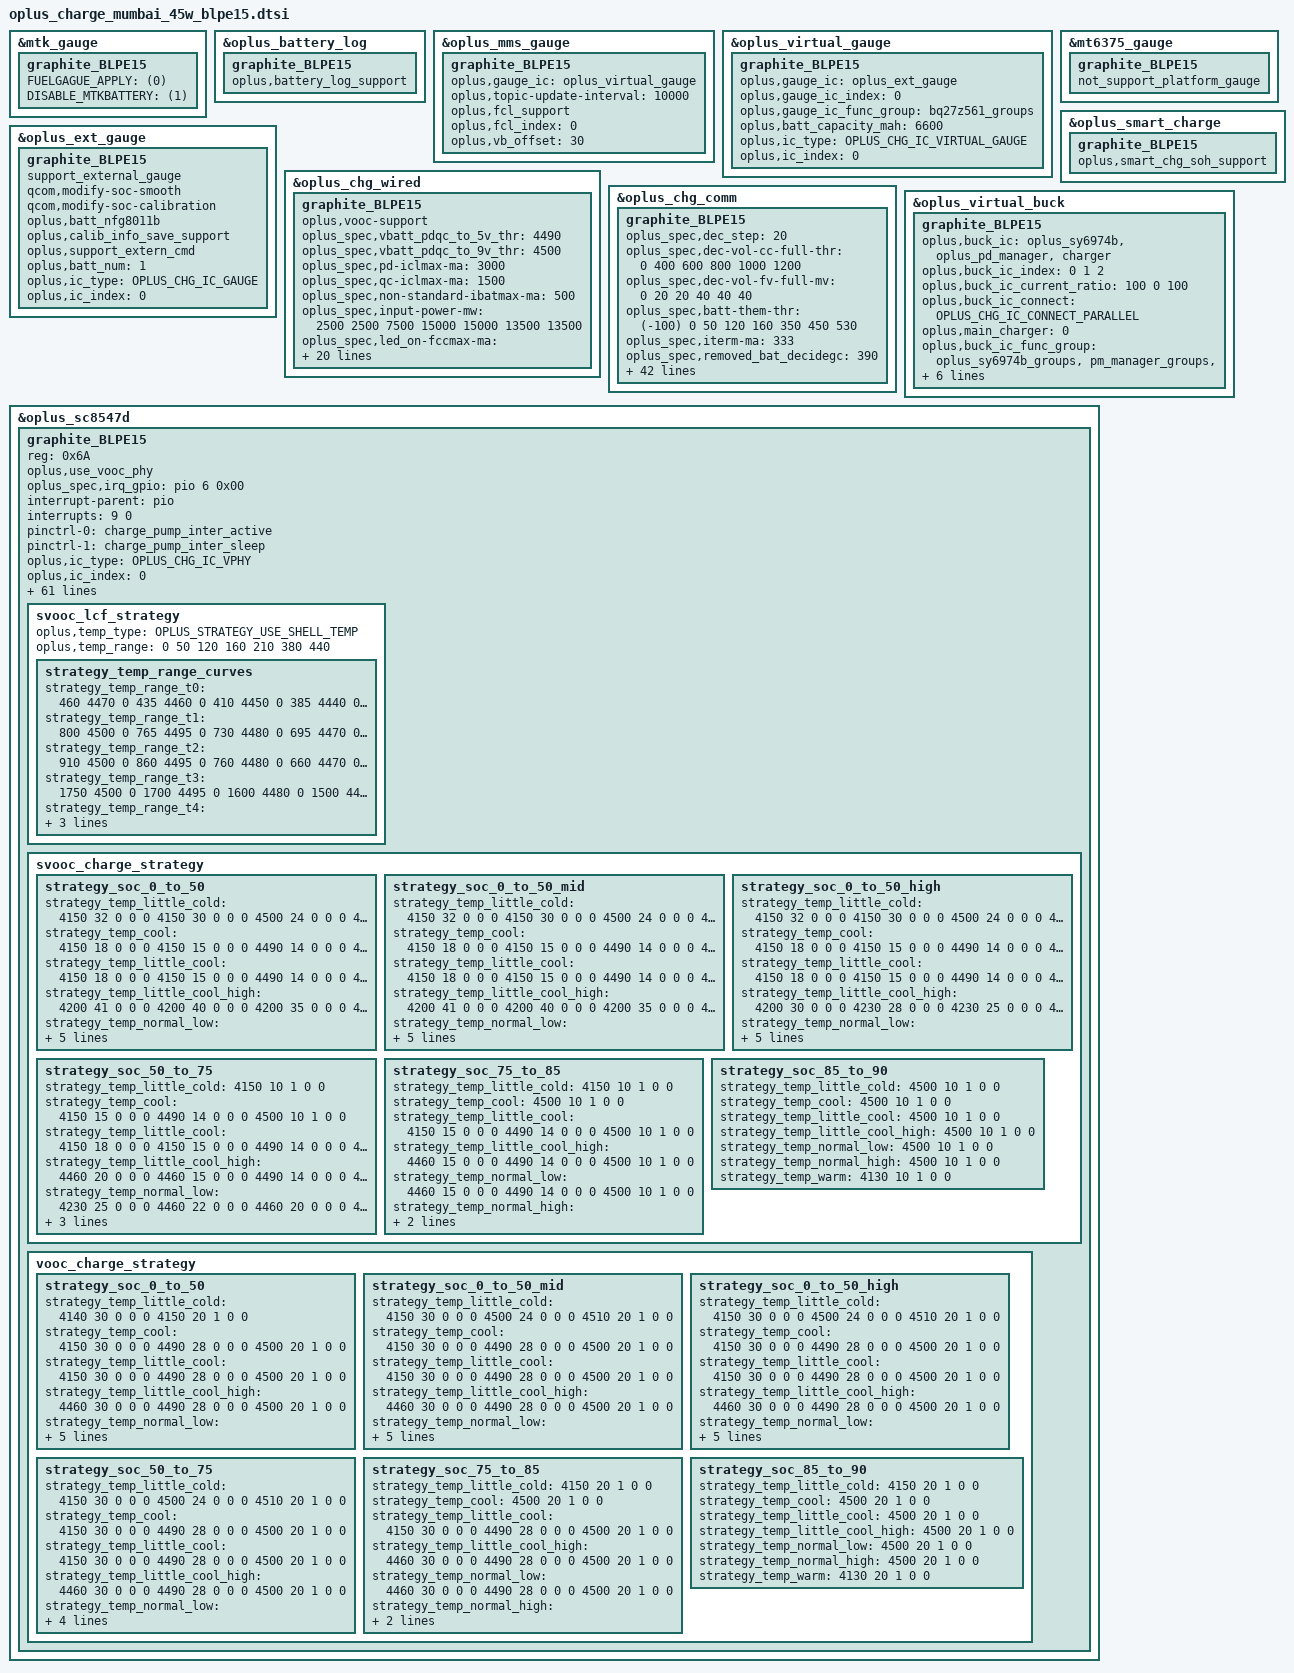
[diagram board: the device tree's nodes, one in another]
// SPDX-License-Identifier: GPL-2.0-only
/*
* Copyright (C) 2021-2020 Oplus. All rights reserved.
*/

/*
 *
 * CPU:MT6835 Barley
 * IRQB
 * CHARGER_PUMP1 (cp irq)               --> GPIO6
 * CC_CNTL_INT_N(cc login irq)          --> GPIO12
 * CHG_INT(main irq)           			--> GPIO3
 * USB_CONTACT_IN_INT           		--> GPIO18
 *
 * GPIO
 * USB_SWITCH_2(uart/ap chagrge)  --> GPIO4
 * VBUS_SHORT(防烧口)           	--> GPIO34
 * CHARGER_PUMP1_SCL               --> GPIO133(CP1_SCL3)
 * CHARGER_PUMP1_SDA               --> GPIO134(CP1_SDA3)
 * CHARGER_buck_SCL & PD_SCL       --> GPIO137(CP1_SCL5)
 * CHARGER_buck_SDA & PD_SDA       --> GPIO138(CP1_SDA5)

 *
 * AP_AUXADC:
 * 0				--> FLASH_LED1_NTC
 * 1				--> NTC_USBCON_TEM (BTB VBUS旁)
 * 2				--> NTC_CHARGE (充电IC旁)
 * 3				--> USB_TEM2_ADC (BB_USB_ADC2)
 * 4				--> USB_TEM1_ADC (BB_USB_ADC1)
 * 5				--> BAT_ID_ADC   (battery id)
 * 6				--> NTC_charging （BTB电池座子旁）
 */


#include <dt-bindings/iio/mt635x-auxadc.h>
#include <dt-bindings/pinctrl/mt6373-pinfunc.h>
#include <dt-bindings/pinctrl/mt65xx.h>
#include "oplus_chg.h"

/* charge start */
&mtk_gauge {
	graphite_BLPE15 {
		FUELGAGUE_APPLY = <(0)>;
		DISABLE_MTKBATTERY = <(1)>;
	};
};

&oplus_battery_log {
	graphite_BLPE15 {
		oplus,battery_log_support;
		};
};

&oplus_mms_gauge {
	graphite_BLPE15 {
		oplus,gauge_ic = <&oplus_virtual_gauge>;
		oplus,topic-update-interval = <10000>;
		oplus,fcl_support;
		oplus,fcl_index = <0>;
		oplus,vb_offset = <30>;
	};
};

&oplus_virtual_gauge {
	graphite_BLPE15 {
			oplus,gauge_ic = <&oplus_ext_gauge>;
			oplus,gauge_ic_index = <0>;
			oplus,gauge_ic_func_group = <&bq27z561_groups>;
			oplus,batt_capacity_mah = <6600>;
			oplus,ic_type = <OPLUS_CHG_IC_VIRTUAL_GAUGE>;
			oplus,ic_index = <0>;
	};
};

&oplus_ext_gauge {
	graphite_BLPE15{
		support_external_gauge;

		qcom,modify-soc-smooth;
		qcom,modify-soc-calibration;
		oplus,batt_nfg8011b;
		oplus,calib_info_save_support;
		oplus,support_extern_cmd;
		oplus,batt_num = <1>;
		oplus,ic_type = <OPLUS_CHG_IC_GAUGE>;
		oplus,ic_index = <0>;
	};
};

&mt6375_gauge {
	graphite_BLPE15{
		not_support_platform_gauge;
	};
};

&oplus_chg_wired {
	graphite_BLPE15 {
		oplus,vooc-support;

		oplus_spec,vbatt_pdqc_to_5v_thr = <4490>;
		oplus_spec,vbatt_pdqc_to_9v_thr = <4500>;
		oplus_spec,pd-iclmax-ma = <3000>;
		oplus_spec,qc-iclmax-ma = <1500>;
		oplus_spec,non-standard-ibatmax-ma = <500>;
		oplus_spec,input-power-mw = <
			2500		/* OPLUS_WIRED_CHG_MODE_UNKNOWN */
			2500		/* OPLUS_WIRED_CHG_MODE_SDP */
			7500		/* OPLUS_WIRED_CHG_MODE_CDP */
			15000		/* OPLUS_WIRED_CHG_MODE_DCP */
			15000		/* OPLUS_WIRED_CHG_MODE_VOOC */
			13500		/* OPLUS_WIRED_CHG_MODE_QC */
			13500		/* OPLUS_WIRED_CHG_MODE_PD */
		>;
		oplus_spec,led_on-fccmax-ma = <0 1024 3073 3300 3300 3300 3300 1000 0>;
	oplus_spec,fccmax-ma-lv = <
			0 1024  2200 2200 2200 2200 2200 2200 0	/* OPLUS_WIRED_CHG_MODE_UNKNOWN */
			0 600   600  600  600  600  600  600  0 /* OPLUS_WIRED_CHG_MODE_SDP */
			0 967   1600 1600 1600 1600 1600 1600 0	/* OPLUS_WIRED_CHG_MODE_CDP */
			0 1024  3069 3300 3300 3300 3300 3300 0	/* OPLUS_WIRED_CHG_MODE_DCP */
			0 967   2200 2200 2200 2200 2200 2200 0	/* OPLUS_WIRED_CHG_MODE_VOOC */
			0 967   2902 3300 3300 3300 3300 3300 0	/* OPLUS_WIRED_CHG_MODE_QC */
			0 967   2902 3300 3300 3300 3300 3300 0	/* OPLUS_WIRED_CHG_MODE_PD */
		>;
		oplus_spec,fccmax-ma-hv = <
			0 1024  2200 2200 2200 2200 2200 2200 0	/* OPLUS_WIRED_CHG_MODE_UNKNOWN */
			0 600   600  600  600  600  600  500  0	/* OPLUS_WIRED_CHG_MODE_SDP */
			0 967   1600 1600 1600 1600 1600 1000 0	/* OPLUS_WIRED_CHG_MODE_CDP */
			0 1024  1705 3300 3300 3300 3300 1000 0	/* OPLUS_WIRED_CHG_MODE_DCP */
			0 967   1612 2200 2200 2200 2200 1000 0	/* OPLUS_WIRED_CHG_MODE_VOOC */
			0 967   1612 3300 3300 3300 3300 1000 0	/* OPLUS_WIRED_CHG_MODE_QC */
			0 967   1612 3300 3300 3300 3300 1000 0	/* OPLUS_WIRED_CHG_MODE_PD */
		>;

		oplus_spec,cool_down_pdqc_vol_mv = <5000 5000 5000 9000>;
		oplus_spec,cool_down_pdqc_curr_ma = <1200 1500 2000 1500>;
		oplus_spec,cool_down_vooc_curr_ma = <1200 1500 2000 2500 3000 3000>;
		oplus_spec,cool_down_normal_curr_ma = <1200 1500 2000>;
		oplus_spec,cool_down_sale_pdqc_vol_mv = <9000>;
		oplus_spec,cool_down_sale_pdqc_curr_ma = <1200>;
		oplus_spec,vbus_ov_thr_mv = <11000 11000>;
		oplus_spec,vbus_uv_thr_mv = <3400 3400>;

		/* first data is strategy used temp type */
                oplus,vooc_strategy_name = "cgcl";
		oplus,vooc_strategy_data = <OPLUS_STRATEGY_USE_BATT_TEMP
					    0   385 4000 1 0
					    385 395 3000 2 0
					    395 420 2000 2 1>;
	};


};

&oplus_chg_comm {
	graphite_BLPE15 {
		oplus_spec,dec_step = <20>;
		oplus_spec,dec-vol-cc-full-thr = <0 400 600 800 1000 1200>;
		oplus_spec,dec-vol-fv-full-mv = <0 20 20 40 40 40>;
		oplus_spec,batt-them-thr = <(-100) 0 50 120 160 350 450 530>;
		oplus_spec,iterm-ma = <333>; /* 6850*0.05+10 */
		oplus_spec,removed_bat_decidegc = <390>; /*-39 degree*/
		oplus_spec,fv-mv = <4450 4450 4450 4450 4450 4450 4450 4130 4130>;
		oplus_spec,sw-fv-mv = <4400 4400 4400 4400 4400 4400 4400 4080 4080>;
		oplus_spec,sw-over-fv-mv = <4460 4460 4460 4460 4460 4460 4460 4140 4140>;
		oplus_spec,wired-vbatdet-mv = <0 4150 4250 4350 4350 4350 4350 4030 0>;
		oplus_spec,hw-fv-inc-mv = <0 18 18 18 18 18 18 18 0>;
		oplus_spec,sw-over-fv-dec-mv = <8>;
		oplus_spec,fcc-gear-thr-mv = <4180>;
		oplus_spec,vbatt-ov-thr-mv = <4600>;
		oplus_spec,vbat_uv_thr_mv = <3300>;
		oplus_spec,vbat_charging_uv_thr_mv = <3200>;

		/* non-standard */
		oplus_spec,non-standard-sw-fv-mv = <3930>;
		oplus_spec,non-standard-fv-mv = <3980>;
		oplus_spec,non-standard-hw-fv-inc-mv = <18>;
		oplus_spec,non-standard-sw-over-fv-mv = <3990>;
		oplus_spec,non-standard-vbatdet-mv = <3680>;

		/* FFC */
		oplus_spec,full_pre_ffc_judge;
		oplus_spec,full-pre-ffc-mv = <4485>;
		oplus_spec,ffc-temp-thr = <120 210 350 440>;
		oplus_spec,wired-ffc-step-max = <5>;
		oplus_spec,wired-ffc-fv-mv = <4580 4580 4580 4580 4580>;
		oplus_spec,wired-ffc-fv-cutoff-mv = <4445 4445 4445
                                                     4445 4445 4445
                                                     4445 4445 4445
                                                     4445 4445 4445
                                                     4445 4445 4445>;
		oplus_spec,wired-ffc-fcc-ma = <1500 1500 1500
					       1400 1400 1400
					       1300 1300 1300
					       1200 1200 1200
					       1100 1100 1100>;
		oplus_spec,wired-ffc-fcc-cutoff-ma = <1350 1350 1350
						      1250 1250 1250
						      1150 1150 1150
						      1050 1050 1050
						      950  950  950>;

		/*If use subboard NTC as battery temp, config it as 20, otherwise 0 */
		oplus_spec,tbatt_power_off_cali_temp = <0>;
		oplus_spec,poweroff_high_batt_temp = <720>;
		oplus_spec,poweroff_emergency_batt_temp = <770>;
		oplus,vooc_show_ui_soc_decimal;
		oplus,ui_soc_decimal_speedmin = <20>;
		oplus,gauge_stuck_jump_support;
		oplus,gauge_stuck_threshold = <15>;
		oplus,gauge_stuck_time = <50>;
		oplus,smooth_switch;
		oplus,reserve_chg_soc = <2>;

	};
};

&oplus_smart_charge {
	graphite_BLPE15 {
		oplus,smart_chg_soh_support;
	};
};

&oplus_virtual_buck {
	graphite_BLPE15 {
		oplus,buck_ic = <&oplus_sy6974b &oplus_pd_manager &charger>;
		oplus,buck_ic_index = <0 1 2>;
		oplus,buck_ic_current_ratio = <100 0 100>;
		oplus,buck_ic_connect = <OPLUS_CHG_IC_CONNECT_PARALLEL>;
		oplus,main_charger = <0>;
		oplus,buck_ic_func_group = <&oplus_sy6974b_groups &pm_manager_groups &mtk_6895_groups>;

		oplus,ic_type = <OPLUS_CHG_IC_VIRTUAL_BUCK>;
		oplus,ic_index = <0>;

		io-channels = <&auxadc 4>, <&auxadc 3>;
		io-channel-names = "usb_temp_adc_l", "usb_temp_adc_r";

		oplus,uart_tx-gpio = <&pio 50 0x00>;
		oplus,uart_rx-gpio = <&pio 51 0x00>;
	};
};

&oplus_sc8547d {
	graphite_BLPE15 {
		reg = <0x6A>;

		//oplus,use_ufcs_phy;
		oplus,use_vooc_phy;
		oplus_spec,irq_gpio = <&pio 6 0x00>;
		interrupt-parent = <&pio>;
		interrupts = <9 0>;

		pinctrl-names = "charging_inter_active", "charging_inter_sleep";
		pinctrl-0 = <&charge_pump_inter_active>;
		pinctrl-1 = <&charge_pump_inter_sleep>;

		oplus,ic_type = <OPLUS_CHG_IC_VPHY>;
		oplus,ic_index = <0>;
		oplus,vooc-version = <VOOC_VERSION_5_0>;

		ocp_reg = <0xf>;
		ovp_reg = <0x36>;/* vbat ovp 4.85v */
		vbus_ovp_reg = /bits/ 8 <0x5A>;
		oplus_spec,slave_cp_enable_thr = <1400>;		//2000-100mA
		oplus_spec,slave_cp_disable_thr_high = <1100>;	//1500+100mA
		oplus_spec,voocphy_current_default = <41>;
		oplus_spec,external_gauge_support;
		oplus_spec,svooc_cool_down_current_limit = <82 20 20 24 30 34 40 44 50 54 60 64 70 74>;
		oplus_spec,vooc_cool_down_current_limit = <30 20 20 24 30 34 40 44 50 54 60 64 70 74>;
		oplus_spec,vooc_bad_volt = <3800 3800 3800 3800>;
		oplus_spec,vooc_bad_volt_suspend = <3800 3800 3800 3800>;
		oplus_spec,vooc_bad_volt_check_head_mask = /bits/ 8 <0x3>; /* VOOC 2.0/VOOC3.0 */
		oplus_spec,ap_control_allow;

		oplus_spec,vooc_low_temp = <50>;
		oplus_spec,vooc_little_cold_temp = <50>;
		oplus_spec,vooc_cool_temp = <120>;
		oplus_spec,vooc_little_cool_temp = <160>;
		oplus_spec,vooc_little_cool_high_temp = <210>;
		oplus_spec,vooc_normal_low_temp = <350>;
		oplus_spec,vooc_normal_high_temp = <440>;
		oplus_spec,vooc_high_temp = <500>;
		oplus_spec,vooc_over_high_temp = <510>;
		oplus_spec,vooc_strategy_normal_current = <122>;
		oplus_spec,vooc_normal_to_little_cool_current = <100>;
		oplus_spec,vooc_multistep_initial_batt_temp = <1000>;
		oplus_spec,fastchg_timeout_time_init = <175620>;

		oplus_spec,vooc_low_soc = <0>;
		oplus_spec,vooc_high_soc = <90>;
		oplus_spec,vooc_warm_vol_thr = <4000>;
		oplus_spec,vooc_warm_soc_thr = <55>;

		oplus_spec,voocphy_freq_mincore = <1800000>;
		oplus_spec,voocphy_freq_midcore = <1800000>;
		oplus_spec,voocphy_freq_maxcore = <1800000>;
		oplus_spec,voocphy_current_change_timeout = <100>;
		oplus_spec,copycat_vooc_support;
		oplus_spec,copycat_vooc_accuracy_value = <105>;
		oplus,copycat-vooc-count = <4>;

		oplus_spec,voocphy_ibat_over_current = <9600>;
		oplus_spec,voocphy_svooc_cp_max_ibus = <4500>;
		oplus_spec,voocphy_vooc_cp_max_ibus = <4500>;
		oplus_spec,voocphy_cp_max_ibus = <4500>;

		oplus,workaround_for_100w;
		oplus_spec,vooc_little_cold_full_voltage = <4470>;
		oplus_spec,vooc_cool_full_voltage = <4500>;
		oplus_spec,vooc_little_cool_full_voltage = <4500>;
		oplus_spec,vooc_little_cool_high_full_voltage = <4500>;
		oplus_spec,vooc_warm_full_voltage = <4130>;
		oplus_spec,vooc_1time_full_voltage = <4510>;
		oplus_spec,vooc_ntime_full_voltage = <4500>;
		oplus_spec,soc_range = <0 20 35 55 75 85 90>;


		svooc_batt_sys_curve = <0 1 0 1 0 0 1	// 4100mA
					1 1 1 1 0 0 0	// 4604mV
					0 0 1 1 0 1 0	// 2600mA
					1 1 1 1 0 0 0	// 4604mV
					0 0 0 1 0 1 1	// 1100mA
					1 1 1 1 0 0 0>;	// 4604mV

		vooc_batt_sys_curve =  <0 0 1 1 1 1 0	// 3000mA
					1 1 1 1 0 0 0	// 4604mV
					0 0 1 1 0 1 0	// 2600mA
					1 1 1 1 0 0 0	// 4604mV
					0 0 0 1 0 1 1	// 1100mA
					1 1 1 1 0 0 0>;	// 4604mV
		svooc_lcf_strategy {
			oplus,temp_type = <OPLUS_STRATEGY_USE_SHELL_TEMP>;
			oplus,temp_range = <0 50 120 160 210 380 440>;

			strategy_temp_range_curves {
				strategy_temp_range_t0 = <460 4470 0
								 435 4460 0
								 410 4450 0
								 385 4440 0
								 360 4430 1>;
				strategy_temp_range_t1 = <800 4500 0
								 765 4495 0
								 730 4480 0
								 695 4470 0
								 660 4460 1>;
				strategy_temp_range_t2 = <910 4500 0
								 860 4495 0
								 760 4480 0
								 660 4470 0
								 510 4460 1>;
				strategy_temp_range_t3 = <1750 4500 0
								 1700 4495 0
								 1600 4480 0
								 1500 4470 0
								 1350 4460 1>;
				strategy_temp_range_t4 = <1750 4500 0
								 1700 4495 0
								 1600 4480 0
								 1500 4470 0
								 1350 4460 1>;
				strategy_temp_range_t5 = <1950 4500 0
								 1900 4495 0
								 1800 4480 0
								 1700 4470 0
								 1550 4460 1>;
			};
		};

		svooc_charge_strategy {
			strategy_soc_0_to_50 { /* 0 ~ 20 */
				strategy_temp_little_cold =	<4150 32 0 0 0
								 4150 30 0 0 0
								 4500 24 0 0 0
								 4510 10 1 0 0>;
				strategy_temp_cool =		<4150 18 0 0 0
								 4150 15 0 0 0
								 4490 14 0 0 0
								 4500 10 1 0 0>;

				strategy_temp_little_cool = 	<4150 18 0 0 0
								 4150 15 0 0 0
								 4490 14 0 0 0
								 4500 10 1 0 0>;

				strategy_temp_little_cool_high =<4200 41 0 0 0
								 4200 40 0 0 0
								 4200 35 0 0 0
								 4200 30 0 0 0
								 4230 28 0 0 0
								 4230 25 0 0 0
								 4460 22 0 0 0
								 4460 20 0 0 0
								 4460 15 0 0 0
								 4490 14 0 0 0
								 4500 10 1 0 0>;

				strategy_temp_normal_low = 	<4200 41 0 0 0
								 4200 40 0 0 0
								 4200 35 0 0 0
								 4200 30 0 0 0
								 4230 28 0 0 0
								 4230 25 0 0 0
								 4460 22 0 0 0
								 4460 20 0 0 0
								 4460 15 0 0 0
								 4490 14 0 0 0
								 4500 10 1 0 0>;

				strategy_temp_normal_high =	<4200 41 0 0 0
								 4200 40 0 0 0
								 4200 35 0 0 0
								 4200 30 0 0 0
								 4230 28 0 0 0
								 4230 25 0 0 0
								 4460 22 0 0 0
								 4460 20 0 0 0
								 4460 15 0 0 0
								 4490 14 0 0 0
								 4500 10 1 0 0>;

				strategy_temp_warm =		<4120 20 0 0 0
								 4120 15 0 0 0
								 4130 10 1 0 0>;
			};

			strategy_soc_0_to_50_mid { /* 21 ~ 35 */
				strategy_temp_little_cold =	<4150 32 0 0 0
								 4150 30 0 0 0
								 4500 24 0 0 0
								 4510 10 1 0 0>;
				strategy_temp_cool =		<4150 18 0 0 0
								 4150 15 0 0 0
								 4490 14 0 0 0
								 4500 10 1 0 0>;

				strategy_temp_little_cool = 	<4150 18 0 0 0
								 4150 15 0 0 0
								 4490 14 0 0 0
								 4500 10 1 0 0>;

				strategy_temp_little_cool_high =<4200 41 0 0 0
								 4200 40 0 0 0
								 4200 35 0 0 0
								 4200 30 0 0 0
								 4230 28 0 0 0
								 4230 25 0 0 0
								 4460 22 0 0 0
								 4460 20 0 0 0
								 4460 15 0 0 0
								 4490 14 0 0 0
								 4500 10 1 0 0>;

				strategy_temp_normal_low = 	<4200 41 0 0 0
								 4200 40 0 0 0
								 4200 35 0 0 0
								 4200 30 0 0 0
								 4230 28 0 0 0
								 4230 25 0 0 0
								 4460 22 0 0 0
								 4460 20 0 0 0
								 4460 15 0 0 0
								 4490 14 0 0 0
								 4500 10 1 0 0>;

				strategy_temp_normal_high =	<4200 41 0 0 0
								 4200 40 0 0 0
								 4200 35 0 0 0
								 4200 30 0 0 0
								 4230 28 0 0 0
								 4230 25 0 0 0
								 4460 22 0 0 0
								 4460 20 0 0 0
								 4460 15 0 0 0
								 4490 14 0 0 0
								 4500 10 1 0 0>;

				strategy_temp_warm =		<4120 20 0 0 0
								 4120 15 0 0 0
								 4130 10 1 0 0>;
			};

			strategy_soc_0_to_50_high { /* 36 ~ 55 */
				strategy_temp_little_cold =	<4150 32 0 0 0
								 4150 30 0 0 0
								 4500 24 0 0 0
								 4510 10 1 0 0>;
				strategy_temp_cool =		<4150 18 0 0 0
								 4150 15 0 0 0
								 4490 14 0 0 0
								 4500 10 1 0 0>;

				strategy_temp_little_cool = 	<4150 18 0 0 0
								 4150 15 0 0 0
								 4490 14 0 0 0
								 4500 10 1 0 0>;

				strategy_temp_little_cool_high =<4200 30 0 0 0
								 4230 28 0 0 0
								 4230 25 0 0 0
								 4460 22 0 0 0
								 4460 20 0 0 0
								 4460 15 0 0 0
								 4490 14 0 0 0
								 4500 10 1 0 0>;

				strategy_temp_normal_low = 	<4200 41 0 0 0
								 4200 40 0 0 0
								 4200 35 0 0 0
								 4200 30 0 0 0
								 4230 28 0 0 0
								 4230 25 0 0 0
								 4460 22 0 0 0
								 4460 20 0 0 0
								 4460 15 0 0 0
								 4490 14 0 0 0
								 4500 10 1 0 0>;

				strategy_temp_normal_high =	<4200 41 0 0 0
								 4200 40 0 0 0
								 4200 35 0 0 0
								 4200 30 0 0 0
								 4230 28 0 0 0
								 4230 25 0 0 0
								 4460 22 0 0 0
								 4460 20 0 0 0
								 4460 15 0 0 0
								 4490 14 0 0 0
								 4500 10 1 0 0>;

				strategy_temp_warm =		<4120 20 0 0 0
								 4120 15 0 0 0
								 4130 10 1 0 0>;
			};
			strategy_soc_50_to_75 { /* 56 ~ 75 */
				strategy_temp_little_cold =	<4150 10 1 0 0>;
				strategy_temp_cool = <4150 15 0 0 0
				                    4490 14 0 0 0
								    4500 10 1 0 0>;
				strategy_temp_little_cool =	<4150 18 0 0 0
								 4150 15 0 0 0
								 4490 14 0 0 0
								 4500 10 1 0 0>;
				strategy_temp_little_cool_high = <4460 20 0 0 0
								 4460 15 0 0 0
								 4490 14 0 0 0
								 4500 10 1 0 0>;
				strategy_temp_normal_low = <4230 25 0 0 0
								 4460 22 0 0 0
								 4460 20 0 0 0
								 4460 15 0 0 0
								 4490 14 0 0 0
								 4500 10 1 0 0>;
				strategy_temp_normal_high =	<4230 25 0 0 0
								 4460 22 0 0 0
								 4460 20 0 0 0
								 4460 15 0 0 0
								 4490 14 0 0 0
								 4500 10 1 0 0>;
				strategy_temp_warm = <4130 10 1 0 0>;
			};

			strategy_soc_75_to_85 {	/*76 ~ 85*/
				strategy_temp_little_cold =	<4150 10 1 0 0>;
				strategy_temp_cool = <4500 10 1 0 0>;
				strategy_temp_little_cool =	<4150 15 0 0 0
								 4490 14 0 0 0
								 4500 10 1 0 0>;
				strategy_temp_little_cool_high = <4460 15 0 0 0
								 4490 14 0 0 0
								 4500 10 1 0 0>;
				strategy_temp_normal_low =	<4460 15 0 0 0
								 4490 14 0 0 0
								 4500 10 1 0 0>;
				strategy_temp_normal_high =	<4460 15 0 0 0
								 4490 14 0 0 0
								 4500 10 1 0 0>;
				strategy_temp_warm = <4130 10 1 0 0>;
			};

			strategy_soc_85_to_90 { /*86 ~ 90*/
				strategy_temp_little_cold =	<4500 10 1 0 0>;
				strategy_temp_cool = <4500 10 1 0 0>;
				strategy_temp_little_cool =	<4500 10 1 0 0>;
				strategy_temp_little_cool_high = <4500 10 1 0 0>;
				strategy_temp_normal_low =	<4500 10 1 0 0>;
				strategy_temp_normal_high =	<4500 10 1 0 0>;
				strategy_temp_warm = <4130 10 1 0 0>;
			};
		};

		vooc_charge_strategy {
			strategy_soc_0_to_50 {
				strategy_temp_little_cold =	<4140 30 0 0 0
								 4150 20 1 0 0>;
				strategy_temp_cool = <4150 30 0 0 0
								 4490 28 0 0 0
								 4500 20 1 0 0>;
				strategy_temp_little_cool =	<4150 30 0 0 0
								 4490 28 0 0 0
								 4500 20 1 0 0>;
				strategy_temp_little_cool_high = <4460 30 0 0 0
								 4490 28 0 0 0
								 4500 20 1 0 0>;
				strategy_temp_normal_low =	<4460 30 0 0 0
								 4490 28 0 0 0
								 4500 20 1 0 0>;
				strategy_temp_normal_high =	<4460 30 0 0 0
								 4490 28 0 0 0
								 4500 20 1 0 0>;
				strategy_temp_warm = <4120 30 0 0 0
								 4130 20 1 0 0>;
			};

			strategy_soc_0_to_50_mid {
				strategy_temp_little_cold =	<4150 30 0 0 0
				                            4500 24 0 0 0
											4510 20 1 0 0>;
				strategy_temp_cool = <4150 30 0 0 0
				                           4490 28 0 0 0
										   4500 20 1 0 0>;
				strategy_temp_little_cool =	<4150 30 0 0 0
				                 4490 28 0 0 0
								 4500 20 1 0 0>;
				strategy_temp_little_cool_high = <4460 30 0 0 0
				                 4490 28 0 0 0
								 4500 20 1 0 0>;
				strategy_temp_normal_low =	<4460 30 0 0 0
				                 4490 28 0 0 0
								 4500 20 1 0 0>;
				strategy_temp_normal_high =	<4460 30 0 0 0
				                 4490 28 0 0 0
								 4500 20 1 0 0>;
				strategy_temp_warm = <4120 30 0 0 0
				                     4130 20 1 0 0>;
			};

			strategy_soc_0_to_50_high {
				strategy_temp_little_cold =	<4150 30 0 0 0
				                                 4500 24 0 0 0
								 4510 20 1 0 0>;
				strategy_temp_cool =<4150 30 0 0 0
				                     4490 28 0 0 0
				                     4500 20 1 0 0>;
				strategy_temp_little_cool =	<4150 30 0 0 0
				                     4490 28 0 0 0
				                     4500 20 1 0 0>;
				strategy_temp_little_cool_high = <4460 30 0 0 0
				                     4490 28 0 0 0
				                     4500 20 1 0 0>;
				strategy_temp_normal_low =	<4460 30 0 0 0
				                     4490 28 0 0 0
				                     4500 20 1 0 0>;
				strategy_temp_normal_high =	<4460 30 0 0 0
				                     4490 28 0 0 0
				                     4500 20 1 0 0>;
				strategy_temp_warm = <4120 30 0 0 0
				                     4130 20 1 0 0>;
			};

			strategy_soc_50_to_75 {
				strategy_temp_little_cold =	<4150 30 0 0 0
				                            4500 24 0 0 0
											4510 20 1 0 0>;
				strategy_temp_cool = <4150 30 0 0 0
				                           4490 28 0 0 0
										   4500 20 1 0 0>;
				strategy_temp_little_cool =	<4150 30 0 0 0
				                           4490 28 0 0 0
										   4500 20 1 0 0>;
				strategy_temp_little_cool_high = <4460 30 0 0 0
				                           4490 28 0 0 0
										   4500 20 1 0 0>;
				strategy_temp_normal_low =	<4460 30 0 0 0
				                           4490 28 0 0 0
										   4500 20 1 0 0>;
				strategy_temp_normal_high =	<4460 30 0 0 0
				                           4490 28 0 0 0
										   4500 20 1 0 0>;
				strategy_temp_warm = <4130 20 1 0 0>;
			};

			strategy_soc_75_to_85 {
				strategy_temp_little_cold =	<4150 20 1 0 0>;
				strategy_temp_cool = <4500 20 1 0 0>;
				strategy_temp_little_cool =	<4150 30 0 0 0
								 4490 28 0 0 0
								 4500 20 1 0 0>;
				strategy_temp_little_cool_high = <4460 30 0 0 0
								 4490 28 0 0 0
								 4500 20 1 0 0>;
				strategy_temp_normal_low =	<4460 30 0 0 0
								 4490 28 0 0 0
								 4500 20 1 0 0>;
				strategy_temp_normal_high =	<4460 30 0 0 0
								 4490 28 0 0 0
								 4500 20 1 0 0>;
				strategy_temp_warm = <4130 20 1 0 0>;
			};

			strategy_soc_85_to_90 {
				strategy_temp_little_cold =	<4150 20 1 0 0>;
				strategy_temp_cool = <4500 20 1 0 0>;
				strategy_temp_little_cool =	<4500 20 1 0 0>;
				strategy_temp_little_cool_high = <4500 20 1 0 0>;
				strategy_temp_normal_low =	<4500 20 1 0 0>;
				strategy_temp_normal_high =	<4500 20 1 0 0>;
				strategy_temp_warm = <4130 20 1 0 0>;
			};
		};
	};
};


#include "mediatek/oplus_charge_mumbai_45w_blpe15_pps.dtsi"
/* chagrge end */
